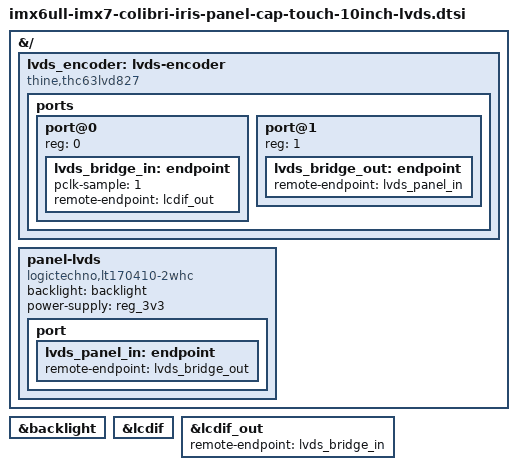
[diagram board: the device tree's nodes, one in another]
// SPDX-License-Identifier: GPL-2.0-only OR MIT
/*
 * Copyright (c) Toradex
 *
 * LVDS transmitter, panel, backlight and LCDIF part of the Toradex Capacitive
 * Touch Display 10.1" LVDS overlays, connected through the Iris v2 carrier
 * board X7 / X5 connectors and the on-carrier LVDS transmitter, shared by the
 * Colibri iMX6ULL eMMC and Colibri iMX7 eMMC overlays.
 *
 * The LVDS transmitter control GPIOs and the Atmel MaxTouch controller wiring
 * are SoC specific and are described by the overlay including this file.
 *
 * https://developer.toradex.com/hardware/accessories/displays/capacitive-touch-display-101inch-lvds
 * https://www.toradex.com/accessories/capacitive-touch-display-10.1-inch-lvds
 * https://developer.toradex.com/hardware/colibri-som-family/carrier-boards/iris-carrier-board/
 * https://www.toradex.com/products/carrier-board/iris-carrier-board
 * https://docs.toradex.com/108421-colibri_arm_iris_carrier_board_datasheet.pdf
 */

&{/} {
	lvds_encoder: lvds-encoder {
		compatible = "thine,thc63lvd827";

		ports {
			#address-cells = <1>;
			#size-cells = <0>;

			port@0 {
				reg = <0>;

				lvds_bridge_in: endpoint {
					pclk-sample = <1>;
					remote-endpoint = <&lcdif_out>;
				};
			};

			port@1 {
				reg = <1>;

				lvds_bridge_out: endpoint {
					remote-endpoint = <&lvds_panel_in>;
				};
			};
		};
	};

	panel-lvds {
		compatible = "logictechno,lt170410-2whc";
		backlight = <&backlight>;
		power-supply = <&reg_3v3>;

		port {
			lvds_panel_in: endpoint {
				remote-endpoint = <&lvds_bridge_out>;
			};
		};
	};
};

&backlight {
	status = "okay";
};

&lcdif {
	status = "okay";
};

&lcdif_out {
	remote-endpoint = <&lvds_bridge_in>;
};
